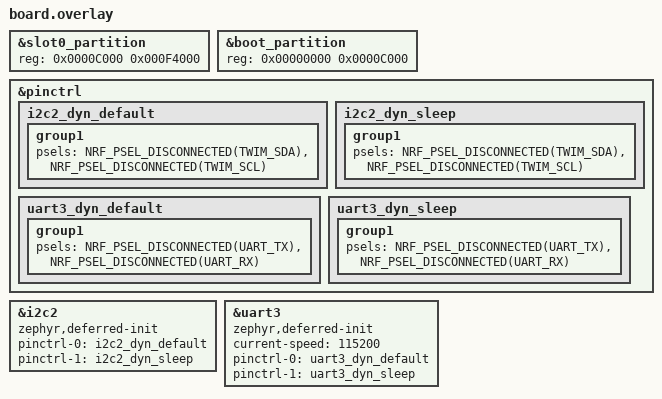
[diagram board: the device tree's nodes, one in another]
/* Remove slot1 (OTA) and storage, expand slot0 to use the space.
 * CircuitPython doesn't use OTA updates, and nothing here uses the settings
 * NVS: CONFIG_BT=n, and CIRCUITPY lives on the external mx25r64. */
&slot0_partition {
	/* Shrink mcuboot to 48KB, absorb slot1 and storage, run to end of flash */
	reg = <0x0000C000 0x000F4000>;
};

&boot_partition {
	reg = <0x00000000 0x0000C000>;
};

&storage_partition {
	reg = <0x000FC000 0x00004000>;
};

/delete-node/ &slot1_partition;
/delete-node/ &storage_partition;

// Enable free serial peripheral instances so CircuitPython can mux them to
// arbitrary pins at runtime. Each instance is enabled in one mode because the
// i2c/spi/uart nodes of an instance are the same peripheral (enforced by
// zephyr/soc/nordic/validate_enabled_instances.c). All signals are
// disconnected and the devices are marked zephyr,deferred-init so nothing is
// claimed at boot; iobroker initializes and routes a device when a busio
// object is constructed and de-initializes it on release.
//
// Instance 0 is left alone: uart0 is the console and i2c0/spi0 share that
// same peripheral, so they must not be enabled. Instance 1 stays with the
// fixed arduino header i2c1, and spi4 stays fixed because it owns the
// MX25R64 flash. The disabled arduino spi3/uart1 nodes keep their devicetree
// pinout in case a shield wants them.

&pinctrl {
	i2c2_dyn_default: i2c2_dyn_default {
		group1 {
			psels = <NRF_PSEL_DISCONNECTED(TWIM_SDA)>,
				<NRF_PSEL_DISCONNECTED(TWIM_SCL)>;
		};
	};

	i2c2_dyn_sleep: i2c2_dyn_sleep {
		group1 {
			psels = <NRF_PSEL_DISCONNECTED(TWIM_SDA)>,
				<NRF_PSEL_DISCONNECTED(TWIM_SCL)>;
		};
	};

	uart3_dyn_default: uart3_dyn_default {
		group1 {
			psels = <NRF_PSEL_DISCONNECTED(UART_TX)>,
				<NRF_PSEL_DISCONNECTED(UART_RX)>;
		};
	};

	uart3_dyn_sleep: uart3_dyn_sleep {
		group1 {
			psels = <NRF_PSEL_DISCONNECTED(UART_TX)>,
				<NRF_PSEL_DISCONNECTED(UART_RX)>;
		};
	};
};

&i2c2 {
	status = "okay";
	zephyr,deferred-init;
	pinctrl-0 = <&i2c2_dyn_default>;
	pinctrl-1 = <&i2c2_dyn_sleep>;
	pinctrl-names = "default", "sleep";
};

&uart3 {
	status = "okay";
	zephyr,deferred-init;
	current-speed = <115200>;
	pinctrl-0 = <&uart3_dyn_default>;
	pinctrl-1 = <&uart3_dyn_sleep>;
	pinctrl-names = "default", "sleep";
};

#include "../../../app.overlay"
